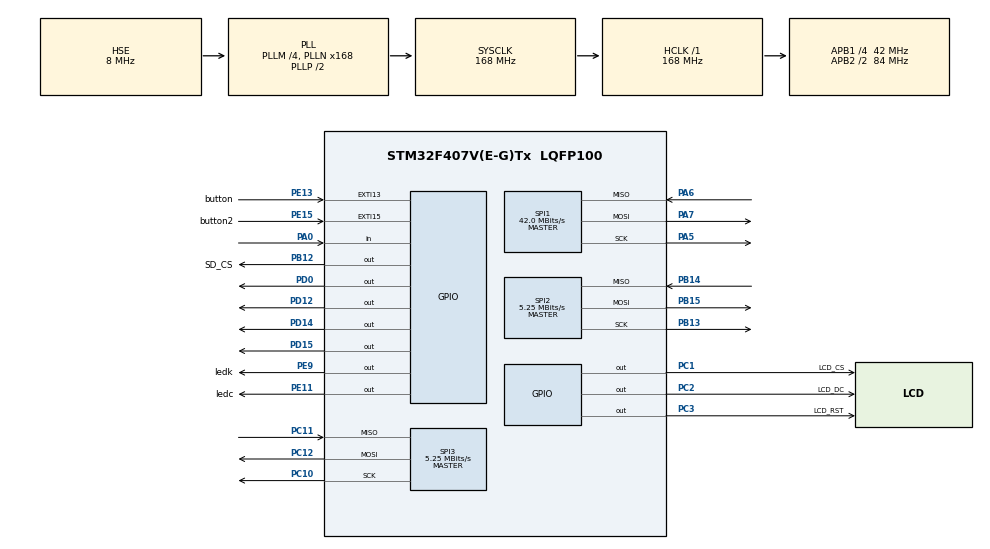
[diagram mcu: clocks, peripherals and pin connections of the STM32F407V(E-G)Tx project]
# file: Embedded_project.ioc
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Mcu.Family=STM32F4
Mcu.Name=STM32F407V(E-G)Tx
Mcu.Package=LQFP100
NVIC.EXTI15_10_IRQn=true\:0\:0\:false\:false\:true\:true\:true\:true
NVIC.PriorityGroup=NVIC_PRIORITYGROUP_4
PA0-WKUP.Signal=GPIO_Input
PA13.Mode=Serial_Wire
PA13.Signal=SYS_JTMS-SWDIO
PA14.Mode=Serial_Wire
PA14.Signal=SYS_JTCK-SWCLK
PA5.Mode=Full_Duplex_Master
PA5.Signal=SPI1_SCK
PA6.Mode=Full_Duplex_Master
PA6.Signal=SPI1_MISO
PA7.Mode=Full_Duplex_Master
PA7.Signal=SPI1_MOSI
PB12.GPIO_Label=SD_CS
PB12.Signal=GPIO_Output
PB13.Mode=Full_Duplex_Master
PB13.Signal=SPI2_SCK
PB14.Mode=Full_Duplex_Master
PB14.Signal=SPI2_MISO
PB15.Mode=Full_Duplex_Master
PB15.Signal=SPI2_MOSI
PC1.GPIO_Label=LCD_CS
PC1.Signal=GPIO_Output
PC10.Mode=Full_Duplex_Master
PC10.Signal=SPI3_SCK
PC11.Mode=Full_Duplex_Master
PC11.Signal=SPI3_MISO
PC12.Mode=Full_Duplex_Master
PC12.Signal=SPI3_MOSI
PC2.GPIO_Label=LCD_DC
PC2.Signal=GPIO_Output
PC3.GPIO_Label=LCD_RST
PC3.Signal=GPIO_Output
PD0.Signal=GPIO_Output
PD12.Signal=GPIO_Output
PD14.Signal=GPIO_Output
PD15.Signal=GPIO_Output
PE11.GPIO_Label=ledc
PE11.Signal=GPIO_Output
PE13.GPIO_Label=button
PE13.GPIO_ModeDefaultEXTI=GPIO_MODE_IT_FALLING
PE13.Signal=GPXTI13
PE15.GPIO_Label=button2
PE15.GPIO_ModeDefaultEXTI=GPIO_MODE_IT_FALLING
PE15.Signal=GPXTI15
PE9.GPIO_Label=ledk
PE9.Signal=GPIO_Output
PH0-OSC_IN.Mode=HSE-External-Oscillator
PH0-OSC_IN.Signal=RCC_OSC_IN
PH1-OSC_OUT.Mode=HSE-External-Oscillator
PH1-OSC_OUT.Signal=RCC_OSC_OUT
ProjectManager.HeapSize=0x200
ProjectManager.StackSize=0x400
ProjectManager.TargetToolchain=STM32CubeIDE
RCC.48MHZClocksFreq_Value=84000000
RCC.AHBFreq_Value=168000000
RCC.APB1CLKDivider=RCC_HCLK_DIV4
RCC.APB1Freq_Value=42000000
RCC.APB1TimFreq_Value=84000000
RCC.APB2CLKDivider=RCC_HCLK_DIV2
RCC.APB2Freq_Value=84000000
RCC.APB2TimFreq_Value=168000000
RCC.CortexFreq_Value=168000000
RCC.HCLKFreq_Value=168000000
RCC.HSE_VALUE=8000000
RCC.HSI_VALUE=16000000
RCC.LSE_VALUE=32768
RCC.PLLM=4
RCC.PLLN=168
RCC.PLLSourceVirtual=RCC_PLLSOURCE_HSE
RCC.SYSCLKFreq_VALUE=168000000
RCC.SYSCLKSource=RCC_SYSCLKSOURCE_PLLCLK
RCC.VCOOutputFreq_Value=336000000
SPI1.CalculateBaudRate=42.0 MBits/s
SPI1.Direction=SPI_DIRECTION_2LINES
SPI1.Mode=SPI_MODE_MASTER
SPI1.VirtualType=VM_MASTER
SPI2.BaudRatePrescaler=SPI_BAUDRATEPRESCALER_8
SPI2.CalculateBaudRate=5.25 MBits/s
SPI2.Direction=SPI_DIRECTION_2LINES
SPI2.Mode=SPI_MODE_MASTER
SPI2.VirtualType=VM_MASTER
SPI3.BaudRatePrescaler=SPI_BAUDRATEPRESCALER_8
SPI3.CalculateBaudRate=5.25 MBits/s
SPI3.Direction=SPI_DIRECTION_2LINES
SPI3.Mode=SPI_MODE_MASTER
SPI3.VirtualType=VM_MASTER
VP_CRC_VS_CRC.Mode=CRC_Activate
VP_FATFS_VS_Generic.Mode=User_defined
board=custom

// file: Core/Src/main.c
/* USER CODE BEGIN Header */
/**
  ******************************************************************************
  * @file           : main.c
  * @brief          : Main program body
  ******************************************************************************
  * @attention
  *
  * Copyright (c) 2025 STMicroelectronics.
  * All rights reserved.
  *
  * This software is licensed under terms that can be found in the LICENSE file
  * in the root directory of this software component.
  * If no LICENSE file comes with this software, it is provided AS-IS.
  *
  ******************************************************************************
  */
/* USER CODE END Header */
#include "main.h"
#include "fatfs.h"

/* USER CODE BEGIN Includes */
#include "rc522.h"
#include "GUI.h"
/* USER CODE END Includes */

CRC_HandleTypeDef hcrc;

SPI_HandleTypeDef hspi1;
SPI_HandleTypeDef hspi2;
SPI_HandleTypeDef hspi3;

void SystemClock_Config(void);
static void MX_GPIO_Init(void);
static void MX_CRC_Init(void);
static void MX_SPI1_Init(void);
static void MX_SPI2_Init(void);
static void MX_SPI3_Init(void);
/* USER CODE BEGIN PFP */
char RFID_Card_Check_ID(char *CardID);
char CheckDataBase(char *CardID);

/* USER CODE END PFP */

int main(void)
{

  /* MCU Configuration--------------------------------------------------------*/

  /* Reset of all peripherals, Initializes the Flash interface and the Systick. */
  HAL_Init();

  /* Configure the system clock */
  SystemClock_Config();

  /* Initialize all configured peripherals */
  MX_GPIO_Init();
  MX_CRC_Init();
  MX_SPI1_Init();
  MX_SPI2_Init();
  MX_SPI3_Init();
  MX_FATFS_Init();
  /* USER CODE BEGIN 2 */
  HAL_Delay(250);
  MFRC522_Init();
  GUI_Init();

  RFID_Reader();

  /* USER CODE END 2 */

  /* Infinite loop */
  while (1)
  {

  }
}

void SystemClock_Config(void)
{
  RCC_OscInitTypeDef RCC_OscInitStruct = {0};
  RCC_ClkInitTypeDef RCC_ClkInitStruct = {0};

  /** Configure the main internal regulator output voltage
  */
  __HAL_RCC_PWR_CLK_ENABLE();
  __HAL_PWR_VOLTAGESCALING_CONFIG(PWR_REGULATOR_VOLTAGE_SCALE1);

  /** Initializes the RCC Oscillators according to the specified parameters
  * in the RCC_OscInitTypeDef structure.
  */
  RCC_OscInitStruct.OscillatorType = RCC_OSCILLATORTYPE_HSE;
  RCC_OscInitStruct.HSEState = RCC_HSE_ON;
  RCC_OscInitStruct.PLL.PLLState = RCC_PLL_ON;
  RCC_OscInitStruct.PLL.PLLSource = RCC_PLLSOURCE_HSE;
  RCC_OscInitStruct.PLL.PLLM = 4;
  RCC_OscInitStruct.PLL.PLLN = 168;
  RCC_OscInitStruct.PLL.PLLP = RCC_PLLP_DIV2;
  RCC_OscInitStruct.PLL.PLLQ = 4;
  if (HAL_RCC_OscConfig(&RCC_OscInitStruct) != HAL_OK)
  {
    Error_Handler();
  }

  /** Initializes the CPU, AHB and APB buses clocks
  */
  RCC_ClkInitStruct.ClockType = RCC_CLOCKTYPE_HCLK|RCC_CLOCKTYPE_SYSCLK
                              |RCC_CLOCKTYPE_PCLK1|RCC_CLOCKTYPE_PCLK2;
  RCC_ClkInitStruct.SYSCLKSource = RCC_SYSCLKSOURCE_PLLCLK;
  RCC_ClkInitStruct.AHBCLKDivider = RCC_SYSCLK_DIV1;
  RCC_ClkInitStruct.APB1CLKDivider = RCC_HCLK_DIV4;
  RCC_ClkInitStruct.APB2CLKDivider = RCC_HCLK_DIV2;

  if (HAL_RCC_ClockConfig(&RCC_ClkInitStruct, FLASH_LATENCY_5) != HAL_OK)
  {
    Error_Handler();
  }
}

static void MX_CRC_Init(void)
{

  hcrc.Instance = CRC;
  if (HAL_CRC_Init(&hcrc) != HAL_OK)
  {
    Error_Handler();
  }

}

static void MX_SPI1_Init(void)
{

  /* SPI1 parameter configuration*/
  hspi1.Instance = SPI1;
  hspi1.Init.Mode = SPI_MODE_MASTER;
  hspi1.Init.Direction = SPI_DIRECTION_2LINES;
  hspi1.Init.DataSize = SPI_DATASIZE_8BIT;
  hspi1.Init.CLKPolarity = SPI_POLARITY_LOW;
  hspi1.Init.CLKPhase = SPI_PHASE_1EDGE;
  hspi1.Init.NSS = SPI_NSS_SOFT;
  hspi1.Init.BaudRatePrescaler = SPI_BAUDRATEPRESCALER_2;
  hspi1.Init.FirstBit = SPI_FIRSTBIT_MSB;
  hspi1.Init.TIMode = SPI_TIMODE_DISABLE;
  hspi1.Init.CRCCalculation = SPI_CRCCALCULATION_DISABLE;
  hspi1.Init.CRCPolynomial = 10;
  if (HAL_SPI_Init(&hspi1) != HAL_OK)
  {
    Error_Handler();
  }

}

static void MX_SPI2_Init(void)
{

  /* SPI2 parameter configuration*/
  hspi2.Instance = SPI2;
  hspi2.Init.Mode = SPI_MODE_MASTER;
  hspi2.Init.Direction = SPI_DIRECTION_2LINES;
  hspi2.Init.DataSize = SPI_DATASIZE_8BIT;
  hspi2.Init.CLKPolarity = SPI_POLARITY_LOW;
  hspi2.Init.CLKPhase = SPI_PHASE_1EDGE;
  hspi2.Init.NSS = SPI_NSS_SOFT;
  hspi2.Init.BaudRatePrescaler = SPI_BAUDRATEPRESCALER_8;
  hspi2.Init.FirstBit = SPI_FIRSTBIT_MSB;
  hspi2.Init.TIMode = SPI_TIMODE_DISABLE;
  hspi2.Init.CRCCalculation = SPI_CRCCALCULATION_DISABLE;
  hspi2.Init.CRCPolynomial = 10;
  if (HAL_SPI_Init(&hspi2) != HAL_OK)
  {
    Error_Handler();
  }

}

static void MX_SPI3_Init(void)
{

  /* SPI3 parameter configuration*/
  hspi3.Instance = SPI3;
  hspi3.Init.Mode = SPI_MODE_MASTER;
  hspi3.Init.Direction = SPI_DIRECTION_2LINES;
  hspi3.Init.DataSize = SPI_DATASIZE_8BIT;
  hspi3.Init.CLKPolarity = SPI_POLARITY_LOW;
  hspi3.Init.CLKPhase = SPI_PHASE_1EDGE;
  hspi3.Init.NSS = SPI_NSS_SOFT;
  hspi3.Init.BaudRatePrescaler = SPI_BAUDRATEPRESCALER_8;
  hspi3.Init.FirstBit = SPI_FIRSTBIT_MSB;
  hspi3.Init.TIMode = SPI_TIMODE_DISABLE;
  hspi3.Init.CRCCalculation = SPI_CRCCALCULATION_DISABLE;
  hspi3.Init.CRCPolynomial = 10;
  if (HAL_SPI_Init(&hspi3) != HAL_OK)
  {
    Error_Handler();
  }

}

static void MX_GPIO_Init(void)
{
  GPIO_InitTypeDef GPIO_InitStruct = {0};

  /* GPIO Ports Clock Enable */
  __HAL_RCC_GPIOH_CLK_ENABLE();
  __HAL_RCC_GPIOC_CLK_ENABLE();
  __HAL_RCC_GPIOA_CLK_ENABLE();
  __HAL_RCC_GPIOE_CLK_ENABLE();
  __HAL_RCC_GPIOB_CLK_ENABLE();
  __HAL_RCC_GPIOD_CLK_ENABLE();

  /*Configure GPIO pin Output Level */
  HAL_GPIO_WritePin(GPIOC, LCD_CS_Pin|LCD_DC_Pin|LCD_RST_Pin, GPIO_PIN_RESET);

  /*Configure GPIO pin Output Level */
  HAL_GPIO_WritePin(GPIOE, ledk_Pin|ledc_Pin, GPIO_PIN_RESET);

  /*Configure GPIO pin Output Level */
  HAL_GPIO_WritePin(SD_CS_GPIO_Port, SD_CS_Pin, GPIO_PIN_RESET);

  /*Configure GPIO pin Output Level */
  HAL_GPIO_WritePin(GPIOD, GPIO_PIN_12|GPIO_PIN_14|GPIO_PIN_15|GPIO_PIN_0, GPIO_PIN_RESET);

  /*Configure GPIO pins : LCD_CS_Pin LCD_DC_Pin LCD_RST_Pin */
  GPIO_InitStruct.Pin = LCD_CS_Pin|LCD_DC_Pin|LCD_RST_Pin;
  GPIO_InitStruct.Mode = GPIO_MODE_OUTPUT_PP;
  GPIO_InitStruct.Pull = GPIO_NOPULL;
  GPIO_InitStruct.Speed = GPIO_SPEED_FREQ_LOW;
  HAL_GPIO_Init(GPIOC, &GPIO_InitStruct);

  /*Configure GPIO pin : PA0 */
  GPIO_InitStruct.Pin = GPIO_PIN_0;
  GPIO_InitStruct.Mode = GPIO_MODE_INPUT;
  GPIO_InitStruct.Pull = GPIO_NOPULL;
  HAL_GPIO_Init(GPIOA, &GPIO_InitStruct);

  /*Configure GPIO pins : ledk_Pin ledc_Pin */
  GPIO_InitStruct.Pin = ledk_Pin|ledc_Pin;
  GPIO_InitStruct.Mode = GPIO_MODE_OUTPUT_PP;
  GPIO_InitStruct.Pull = GPIO_NOPULL;
  GPIO_InitStruct.Speed = GPIO_SPEED_FREQ_LOW;
  HAL_GPIO_Init(GPIOE, &GPIO_InitStruct);

  /*Configure GPIO pins : button_Pin button2_Pin */
  GPIO_InitStruct.Pin = button_Pin|button2_Pin;
  GPIO_InitStruct.Mode = GPIO_MODE_IT_FALLING;
  GPIO_InitStruct.Pull = GPIO_NOPULL;
  HAL_GPIO_Init(GPIOE, &GPIO_InitStruct);

  /*Configure GPIO pin : SD_CS_Pin */
  GPIO_InitStruct.Pin = SD_CS_Pin;
  GPIO_InitStruct.Mode = GPIO_MODE_OUTPUT_PP;
  GPIO_InitStruct.Pull = GPIO_NOPULL;
  GPIO_InitStruct.Speed = GPIO_SPEED_FREQ_LOW;
  HAL_GPIO_Init(SD_CS_GPIO_Port, &GPIO_InitStruct);

  /*Configure GPIO pins : PD12 PD14 PD15 PD0 */
  GPIO_InitStruct.Pin = GPIO_PIN_12|GPIO_PIN_14|GPIO_PIN_15|GPIO_PIN_0;
  GPIO_InitStruct.Mode = GPIO_MODE_OUTPUT_PP;
  GPIO_InitStruct.Pull = GPIO_NOPULL;
  GPIO_InitStruct.Speed = GPIO_SPEED_FREQ_LOW;
  HAL_GPIO_Init(GPIOD, &GPIO_InitStruct);

  /* EXTI interrupt init*/
  HAL_NVIC_SetPriority(EXTI15_10_IRQn, 0, 0);
  HAL_NVIC_EnableIRQ(EXTI15_10_IRQn);

}

void Error_Handler(void)
{
  __disable_irq();
  while (1)
  {
  }
}
